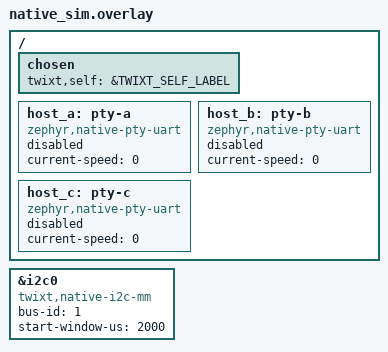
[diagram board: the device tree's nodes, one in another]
/*
 * Copyright (c) 2026 Christoph Jans <jans.christoph@gmail.com>
 *
 * SPDX-License-Identifier: Apache-2.0
 */

/* The bus on native_sim (twixt,native-i2c-mm); TWIXT_SELF_LABEL is mcu_<MCU> */

/ {
	chosen {
		twixt,self = &TWIXT_SELF_LABEL;
	};

	/* The gateway's ports to the laptop (gateway.overlay enables them):
	 * "pty-a connected to pseudotty: /dev/pts/N"
	 */
	host_a: pty-a {
		compatible = "zephyr,native-pty-uart";
		current-speed = <0>;
		status = "disabled";
	};

	host_b: pty-b {
		compatible = "zephyr,native-pty-uart";
		current-speed = <0>;
		status = "disabled";
	};

	host_c: pty-c {
		compatible = "zephyr,native-pty-uart";
		current-speed = <0>;
		status = "disabled";
	};
};

&i2c0 {
	compatible = "twixt,native-i2c-mm";
	bus-id = <1>;
	start-window-us = <2000>;

#include "../twixt_mcus.dtsi"
};
